# MSP432E401Y register map
Vendor: Texas Instruments; File version: 3.200
CPU: CM4 r1p2, little endian, no MPU, no FPU, 0x3 interrupt priority bits, 0x0 interrupts
Registers are 32-bit, read-write, no defined reset value unless marked. A register's access mark holds for its fields unless they carry their own. Offsets are from the block's base; [hi:lo] are bit positions; {n}, {i} and the like mark numbered series.

## ADC0 — Register map for ADC0 peripheral
Base 0x40038000; register names take the prefix ADC0
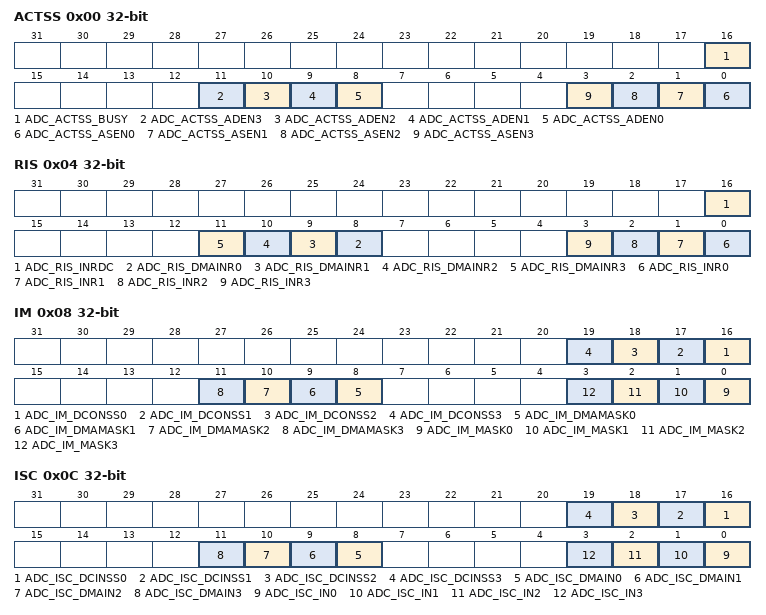
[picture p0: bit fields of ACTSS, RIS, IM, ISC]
0x00 ACTSS — ADC Active Sample Sequencer
  [16] ADC_ACTSS_BUSY — ADC Busy
  [11] ADC_ACTSS_ADEN3 — ADC SS3 DMA Enable
  [10] ADC_ACTSS_ADEN2 — ADC SS2 DMA Enable
  [9] ADC_ACTSS_ADEN1 — ADC SS1 DMA Enable
  [8] ADC_ACTSS_ADEN0 — ADC SS1 DMA Enable
  [n] ADC_ACTSS_ASEN{n} (n=0..3) — ADC SS{n} Enable
0x04 RIS — ADC Raw Interrupt Status
  [16] ADC_RIS_INRDC — Digital Comparator Raw Interrupt Status
  [n+8] ADC_RIS_DMAINR{n} (n=0..3) — SS{n} DMA Raw Interrupt Status
  [n] ADC_RIS_INR{n} (n=0..3) — SS{n} Raw Interrupt Status
0x08 IM — ADC Interrupt Mask
  [n+16] ADC_IM_DCONSS{n} (n=0..3) — Digital Comparator Interrupt on SS{n}
  [n+8] ADC_IM_DMAMASK{n} (n=0..3) — SS{n} DMA Interrupt Mask
  [n] ADC_IM_MASK{n} (n=0..3) — SS{n} Interrupt Mask
0x0C ISC — ADC Interrupt Status and Clear
  [n+16] ADC_ISC_DCINSS{n} (n=0..3) — Digital Comparator Interrupt Status on SS{n}
  [n+8] ADC_ISC_DMAIN{n} (n=0..3) — SS{n} DMA Interrupt Status and Clear
  [n] ADC_ISC_IN{n} (n=0..3) — SS{n} Interrupt Status and Clear
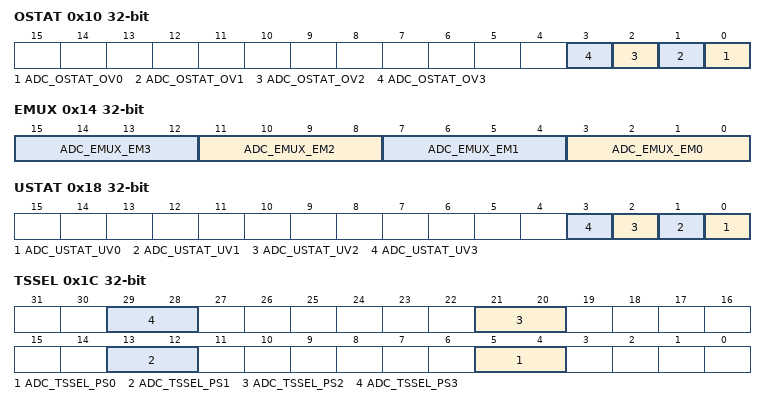
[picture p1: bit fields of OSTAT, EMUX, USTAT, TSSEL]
0x10 OSTAT — ADC Overflow Status
  [n] ADC_OSTAT_OV{n} (n=0..3) — SS{n} FIFO Overflow
0x14 EMUX — ADC Event Multiplexer Select
  [4n+3:4n] ADC_EMUX_EM{n} (n=0..3) — SS{n} Trigger Select
    0=ADC_EMUX_EM{n}_PROCESSOR (Processor (default)); 1=ADC_EMUX_EM{n}_COMP0 (Analog Comparator 0); 2=ADC_EMUX_EM{n}_COMP1 (Analog Comparator 1); 3=ADC_EMUX_EM{n}_COMP2 (Analog Comparator 2); 4=ADC_EMUX_EM{n}_EXTERNAL (External (GPIO Pins)); 5=ADC_EMUX_EM{n}_TIMER (Timer); {v}=ADC_EMUX_EM{n}_PWM{v-6} (PWM generator {v-6}) (v=6..9); 14=ADC_EMUX_EM{n}_NEVER (Never Trigger); 15=ADC_EMUX_EM{n}_ALWAYS (Always (continuously sample))
0x18 USTAT — ADC Underflow Status
  [n] ADC_USTAT_UV{n} (n=0..3) — SS{n} FIFO Underflow
0x1C TSSEL — ADC Trigger Source Select
  [8n+5:8n+4] ADC_TSSEL_PS{n} (n=0..3) — Generator {n} PWM Module Trigger Select
    0=Use Generator {n} (and its trigger) in PWM module 0
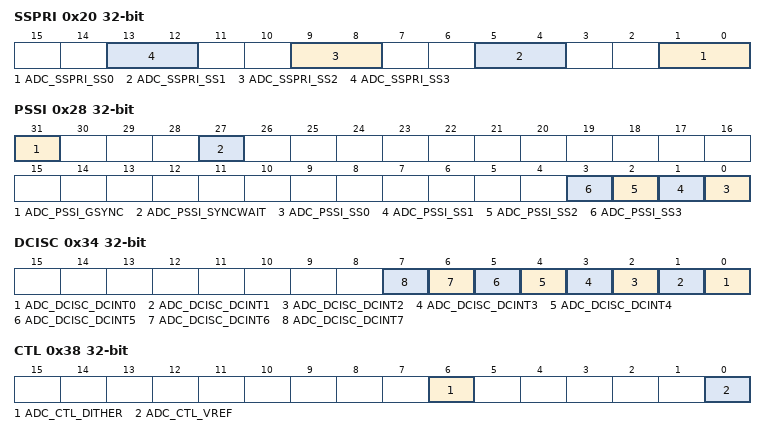
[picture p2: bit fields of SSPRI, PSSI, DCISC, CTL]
0x20 SSPRI — ADC Sample Sequencer Priority
  [4n+1:4n] ADC_SSPRI_SS{n} (n=0..3) — SS{n} Priority
0x24 SPC — ADC Sample Phase Control
  [3:0] ADC_SPC_PHASE — Phase Difference
    0=ADC sample lags by 0.0; 1=ADC_SPC_PHASE_22_5 (ADC sample lags by 22.5); 2=ADC sample lags by 45.0; 3=ADC_SPC_PHASE_67_5 (ADC sample lags by 67.5); 4=ADC sample lags by 90.0; 5=ADC_SPC_PHASE_112_5 (ADC sample lags by 112.5); 6=ADC sample lags by 135.0; 7=ADC_SPC_PHASE_157_5 (ADC sample lags by 157.5); 8=ADC sample lags by 180.0; 9=ADC_SPC_PHASE_202_5 (ADC sample lags by 202.5); 10=ADC sample lags by 225.0; 11=ADC_SPC_PHASE_247_5 (ADC sample lags by 247.5); 12=ADC sample lags by 270.0; 13=ADC_SPC_PHASE_292_5 (ADC sample lags by 292.5); 14=ADC sample lags by 315.0; 15=ADC_SPC_PHASE_337_5 (ADC sample lags by 337.5)
0x28 PSSI — ADC Processor Sample Sequence Initiate
  [31] ADC_PSSI_GSYNC — Global Synchronize
  [27] ADC_PSSI_SYNCWAIT — Synchronize Wait
  [n] ADC_PSSI_SS{n} (n=0..3) — SS{n} Initiate
0x30 SAC — ADC Sample Averaging Control
  [2:0] ADC_SAC_AVG — Hardware Averaging Control
    0=ADC_SAC_AVG_OFF (No hardware oversampling); 1=ADC_SAC_AVG_2X (2x hardware oversampling); 2=ADC_SAC_AVG_4X (4x hardware oversampling); 3=ADC_SAC_AVG_8X (8x hardware oversampling); 4=ADC_SAC_AVG_16X (16x hardware oversampling); 5=ADC_SAC_AVG_32X (32x hardware oversampling); 6=ADC_SAC_AVG_64X (64x hardware oversampling)
0x34 DCISC — ADC Digital Comparator Interrupt Status and Clear
  [n] ADC_DCISC_DCINT{n} (n=0..7) — Digital Comparator {n} Interrupt Status and Clear
0x38 CTL — ADC Control
  [6] ADC_CTL_DITHER — Dither Mode Enable
  [0] ADC_CTL_VREF — Voltage Reference Select
    0=ADC_CTL_VREF_INTERNAL (VDDA and GNDA are the voltage references); 1=ADC_CTL_VREF_EXT_3V (The external VREFA+ and VREFA- inputs are the voltage references)
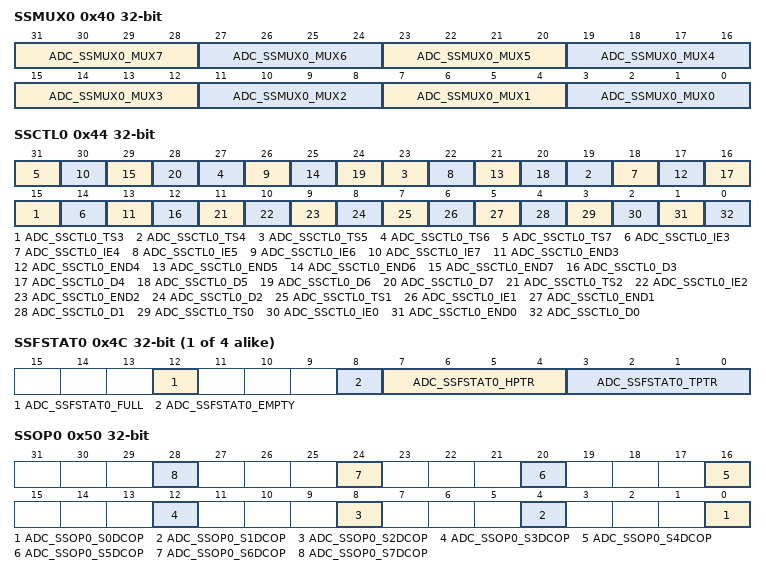
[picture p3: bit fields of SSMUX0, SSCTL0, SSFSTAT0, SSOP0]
0x40 SSMUX0 — ADC Sample Sequence Input Multiplexer Select 0
  [4n+3:4n] ADC_SSMUX0_MUX{n} (n=3..7) — {n+1}th Sample Input Select
  [11:8] ADC_SSMUX0_MUX2 — 3rd Sample Input Select
  [7:4] ADC_SSMUX0_MUX1 — 2nd Sample Input Select
  [3:0] ADC_SSMUX0_MUX0 — 1st Sample Input Select
0x44 SSCTL0 — ADC Sample Sequence Control 0
  [4n+3] ADC_SSCTL0_TS{n} (n=3..7) — {n+1}th Sample Temp Sensor Select
  [4n+2] ADC_SSCTL0_IE{n} (n=3..7) — {n+1}th Sample Interrupt Enable
  [4n+1] ADC_SSCTL0_END{n} (n=3..7) — {n+1}th Sample is End of Sequence
  [4n] ADC_SSCTL0_D{n} (n=3..7) — {n+1}th Sample Differential Input Select
  [11] ADC_SSCTL0_TS2 — 3rd Sample Temp Sensor Select
  [10] ADC_SSCTL0_IE2 — 3rd Sample Interrupt Enable
  [9] ADC_SSCTL0_END2 — 3rd Sample is End of Sequence
  [8] ADC_SSCTL0_D2 — 3rd Sample Differential Input Select
  [7] ADC_SSCTL0_TS1 — 2nd Sample Temp Sensor Select
  [6] ADC_SSCTL0_IE1 — 2nd Sample Interrupt Enable
  [5] ADC_SSCTL0_END1 — 2nd Sample is End of Sequence
  [4] ADC_SSCTL0_D1 — 2nd Sample Differential Input Select
  [3] ADC_SSCTL0_TS0 — 1st Sample Temp Sensor Select
  [2] ADC_SSCTL0_IE0 — 1st Sample Interrupt Enable
  [1] ADC_SSCTL0_END0 — 1st Sample is End of Sequence
  [0] ADC_SSCTL0_D0 — 1st Sample Differential Input Select
{0x48+0x20*i} SSFIFO{i} (i=0..3) — ADC Sample Sequence Result FIFO {i}
  [11:0] ADC_SSFIFO{i}_DATA — Conversion Result Data
{0x4C+0x20*i} SSFSTAT{i} (i=0..3) — ADC Sample Sequence FIFO {i} Status
  [12] ADC_SSFSTAT{i}_FULL — FIFO Full
  [8] ADC_SSFSTAT{i}_EMPTY — FIFO Empty
  [7:4] ADC_SSFSTAT{i}_HPTR — FIFO Head Pointer
  [3:0] ADC_SSFSTAT{i}_TPTR — FIFO Tail Pointer
0x50 SSOP0 — ADC Sample Sequence 0 Operation
  [4n] ADC_SSOP0_S{n}DCOP (n=0..7) — Sample {n} Digital Comparator Operation
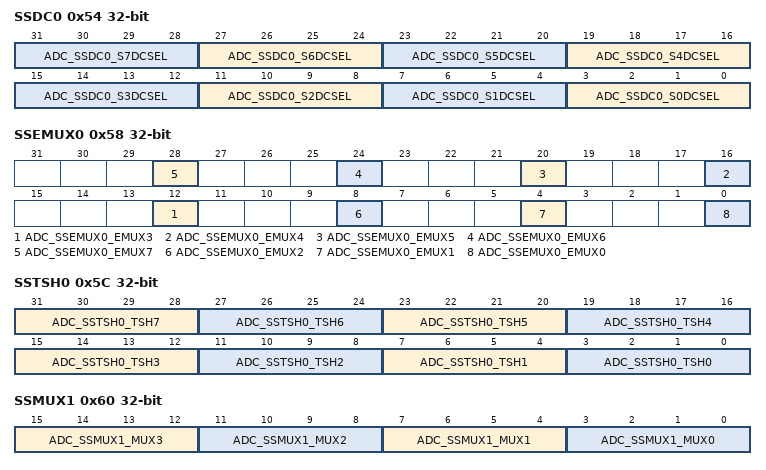
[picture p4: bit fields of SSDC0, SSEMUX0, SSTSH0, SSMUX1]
0x54 SSDC0 — ADC Sample Sequence 0 Digital Comparator Select
  [4n+3:4n] ADC_SSDC0_S{n}DCSEL (n=0..7) — Sample {n} Digital Comparator Select
0x58 SSEMUX0 — ADC Sample Sequence Extended Input Multiplexer Select 0
  [4n] ADC_SSEMUX0_EMUX{n} (n=3..7) — {n+1}th Sample Input Select (Upper Bit)
  [8] ADC_SSEMUX0_EMUX2 — 3rd Sample Input Select (Upper Bit)
  [4] ADC_SSEMUX0_EMUX1 — 2th Sample Input Select (Upper Bit)
  [0] ADC_SSEMUX0_EMUX0 — 1st Sample Input Select (Upper Bit)
0x5C SSTSH0 — ADC Sample Sequence 0 Sample and Hold Time
  [4n+3:4n] ADC_SSTSH0_TSH{n} (n=3..7) — {n+1}th Sample and Hold Period Select
  [11:8] ADC_SSTSH0_TSH2 — 3rd Sample and Hold Period Select
  [7:4] ADC_SSTSH0_TSH1 — 2nd Sample and Hold Period Select
  [3:0] ADC_SSTSH0_TSH0 — 1st Sample and Hold Period Select
0x60 SSMUX1 — ADC Sample Sequence Input Multiplexer Select 1
  [15:12] ADC_SSMUX1_MUX3 — 4th Sample Input Select
  [11:8] ADC_SSMUX1_MUX2 — 3rd Sample Input Select
  [7:4] ADC_SSMUX1_MUX1 — 2nd Sample Input Select
  [3:0] ADC_SSMUX1_MUX0 — 1st Sample Input Select
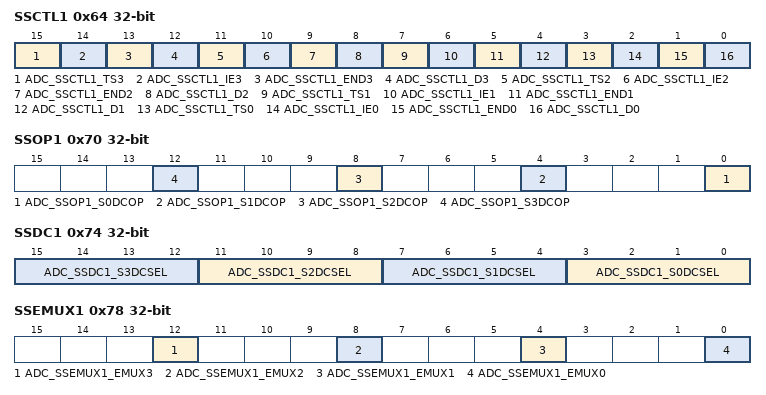
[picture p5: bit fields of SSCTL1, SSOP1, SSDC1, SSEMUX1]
0x64 SSCTL1 — ADC Sample Sequence Control 1
  [15] ADC_SSCTL1_TS3 — 4th Sample Temp Sensor Select
  [14] ADC_SSCTL1_IE3 — 4th Sample Interrupt Enable
  [13] ADC_SSCTL1_END3 — 4th Sample is End of Sequence
  [12] ADC_SSCTL1_D3 — 4th Sample Differential Input Select
  [11] ADC_SSCTL1_TS2 — 3rd Sample Temp Sensor Select
  [10] ADC_SSCTL1_IE2 — 3rd Sample Interrupt Enable
  [9] ADC_SSCTL1_END2 — 3rd Sample is End of Sequence
  [8] ADC_SSCTL1_D2 — 3rd Sample Differential Input Select
  [7] ADC_SSCTL1_TS1 — 2nd Sample Temp Sensor Select
  [6] ADC_SSCTL1_IE1 — 2nd Sample Interrupt Enable
  [5] ADC_SSCTL1_END1 — 2nd Sample is End of Sequence
  [4] ADC_SSCTL1_D1 — 2nd Sample Differential Input Select
  [3] ADC_SSCTL1_TS0 — 1st Sample Temp Sensor Select
  [2] ADC_SSCTL1_IE0 — 1st Sample Interrupt Enable
  [1] ADC_SSCTL1_END0 — 1st Sample is End of Sequence
  [0] ADC_SSCTL1_D0 — 1st Sample Differential Input Select
0x70 SSOP1 — ADC Sample Sequence 1 Operation
  [4n] ADC_SSOP1_S{n}DCOP (n=0..3) — Sample {n} Digital Comparator Operation
0x74 SSDC1 — ADC Sample Sequence 1 Digital Comparator Select
  [4n+3:4n] ADC_SSDC1_S{n}DCSEL (n=0..3) — Sample {n} Digital Comparator Select
0x78 SSEMUX1 — ADC Sample Sequence Extended Input Multiplexer Select 1
  [12] ADC_SSEMUX1_EMUX3 — 4th Sample Input Select (Upper Bit)
  [8] ADC_SSEMUX1_EMUX2 — 3rd Sample Input Select (Upper Bit)
  [4] ADC_SSEMUX1_EMUX1 — 2th Sample Input Select (Upper Bit)
  [0] ADC_SSEMUX1_EMUX0 — 1st Sample Input Select (Upper Bit)
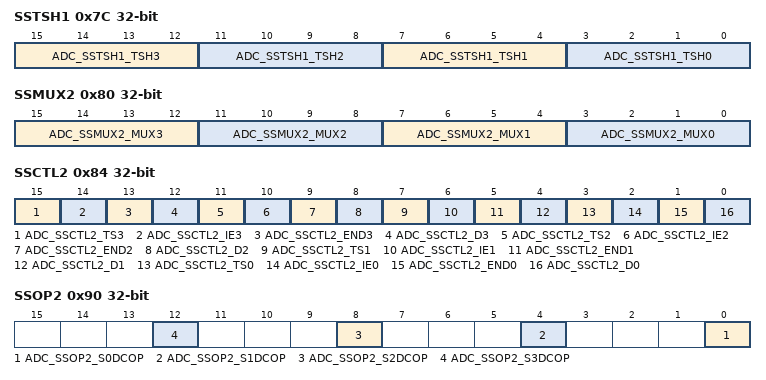
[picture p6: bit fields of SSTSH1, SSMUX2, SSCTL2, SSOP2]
0x7C SSTSH1 — ADC Sample Sequence 1 Sample and Hold Time
  [15:12] ADC_SSTSH1_TSH3 — 4th Sample and Hold Period Select
  [11:8] ADC_SSTSH1_TSH2 — 3rd Sample and Hold Period Select
  [7:4] ADC_SSTSH1_TSH1 — 2nd Sample and Hold Period Select
  [3:0] ADC_SSTSH1_TSH0 — 1st Sample and Hold Period Select
0x80 SSMUX2 — ADC Sample Sequence Input Multiplexer Select 2
  [15:12] ADC_SSMUX2_MUX3 — 4th Sample Input Select
  [11:8] ADC_SSMUX2_MUX2 — 3rd Sample Input Select
  [7:4] ADC_SSMUX2_MUX1 — 2nd Sample Input Select
  [3:0] ADC_SSMUX2_MUX0 — 1st Sample Input Select
0x84 SSCTL2 — ADC Sample Sequence Control 2
  [15] ADC_SSCTL2_TS3 — 4th Sample Temp Sensor Select
  [14] ADC_SSCTL2_IE3 — 4th Sample Interrupt Enable
  [13] ADC_SSCTL2_END3 — 4th Sample is End of Sequence
  [12] ADC_SSCTL2_D3 — 4th Sample Differential Input Select
  [11] ADC_SSCTL2_TS2 — 3rd Sample Temp Sensor Select
  [10] ADC_SSCTL2_IE2 — 3rd Sample Interrupt Enable
  [9] ADC_SSCTL2_END2 — 3rd Sample is End of Sequence
  [8] ADC_SSCTL2_D2 — 3rd Sample Differential Input Select
  [7] ADC_SSCTL2_TS1 — 2nd Sample Temp Sensor Select
  [6] ADC_SSCTL2_IE1 — 2nd Sample Interrupt Enable
  [5] ADC_SSCTL2_END1 — 2nd Sample is End of Sequence
  [4] ADC_SSCTL2_D1 — 2nd Sample Differential Input Select
  [3] ADC_SSCTL2_TS0 — 1st Sample Temp Sensor Select
  [2] ADC_SSCTL2_IE0 — 1st Sample Interrupt Enable
  [1] ADC_SSCTL2_END0 — 1st Sample is End of Sequence
  [0] ADC_SSCTL2_D0 — 1st Sample Differential Input Select
0x90 SSOP2 — ADC Sample Sequence 2 Operation
  [4n] ADC_SSOP2_S{n}DCOP (n=0..3) — Sample {n} Digital Comparator Operation
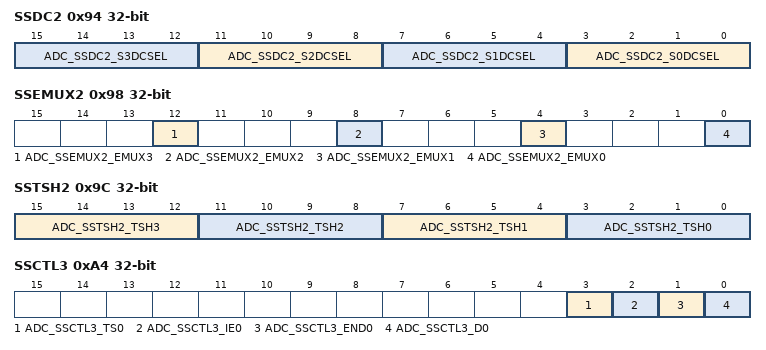
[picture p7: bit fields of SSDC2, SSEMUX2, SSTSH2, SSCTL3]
0x94 SSDC2 — ADC Sample Sequence 2 Digital Comparator Select
  [4n+3:4n] ADC_SSDC2_S{n}DCSEL (n=0..3) — Sample {n} Digital Comparator Select
0x98 SSEMUX2 — ADC Sample Sequence Extended Input Multiplexer Select 2
  [12] ADC_SSEMUX2_EMUX3 — 4th Sample Input Select (Upper Bit)
  [8] ADC_SSEMUX2_EMUX2 — 3rd Sample Input Select (Upper Bit)
  [4] ADC_SSEMUX2_EMUX1 — 2th Sample Input Select (Upper Bit)
  [0] ADC_SSEMUX2_EMUX0 — 1st Sample Input Select (Upper Bit)
0x9C SSTSH2 — ADC Sample Sequence 2 Sample and Hold Time
  [15:12] ADC_SSTSH2_TSH3 — 4th Sample and Hold Period Select
  [11:8] ADC_SSTSH2_TSH2 — 3rd Sample and Hold Period Select
  [7:4] ADC_SSTSH2_TSH1 — 2nd Sample and Hold Period Select
  [3:0] ADC_SSTSH2_TSH0 — 1st Sample and Hold Period Select
0xA0 SSMUX3 — ADC Sample Sequence Input Multiplexer Select 3
  [3:0] ADC_SSMUX3_MUX0 — 1st Sample Input Select
0xA4 SSCTL3 — ADC Sample Sequence Control 3
  [3] ADC_SSCTL3_TS0 — 1st Sample Temp Sensor Select
  [2] ADC_SSCTL3_IE0 — Sample Interrupt Enable
  [1] ADC_SSCTL3_END0 — End of Sequence
  [0] ADC_SSCTL3_D0 — Sample Differential Input Select
0xB0 SSOP3 — ADC Sample Sequence 3 Operation
  [0] ADC_SSOP3_S0DCOP — Sample 0 Digital Comparator Operation
0xB4 SSDC3 — ADC Sample Sequence 3 Digital Comparator Select
  [3:0] ADC_SSDC3_S0DCSEL — Sample 0 Digital Comparator Select
0xB8 SSEMUX3 — ADC Sample Sequence Extended Input Multiplexer Select 3
  [0] ADC_SSEMUX3_EMUX0 — 1st Sample Input Select (Upper Bit)
0xBC SSTSH3 — ADC Sample Sequence 3 Sample and Hold Time
  [3:0] ADC_SSTSH3_TSH0 — 1st Sample and Hold Period Select
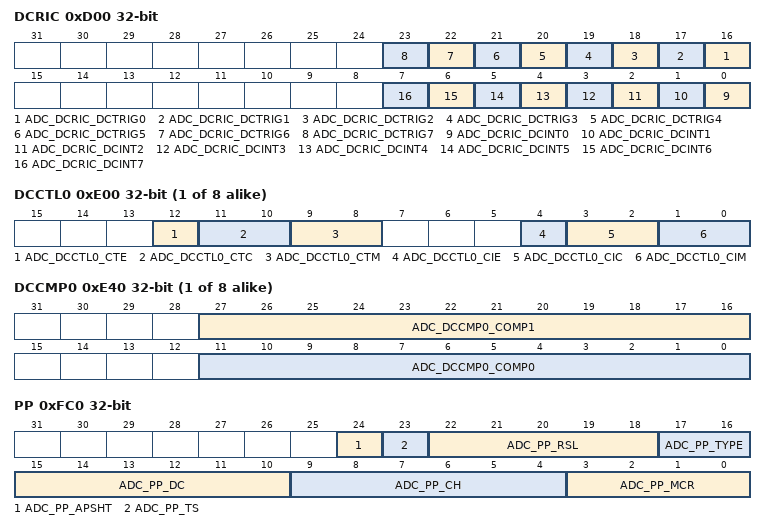
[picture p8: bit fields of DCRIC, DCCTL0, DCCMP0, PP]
0xD00 DCRIC wo — ADC Digital Comparator Reset Initial Conditions
  [n+16] ADC_DCRIC_DCTRIG{n} (n=0..7) — Digital Comparator Trigger {n}
  [n] ADC_DCRIC_DCINT{n} (n=0..7) — Digital Comparator Interrupt {n}
{0xE00+4i} DCCTL{i} (i=0..7) — ADC Digital Comparator Control {i}
  [12] ADC_DCCTL{i}_CTE — Comparison Trigger Enable
  [11:10] ADC_DCCTL{i}_CTC — Comparison Trigger Condition
    0=ADC_DCCTL{i}_CTC_LOW (Low Band); 1=ADC_DCCTL{i}_CTC_MID (Mid Band); 3=ADC_DCCTL{i}_CTC_HIGH (High Band)
  [9:8] ADC_DCCTL{i}_CTM — Comparison Trigger Mode
    0=ADC_DCCTL{i}_CTM_ALWAYS (Always); 1=ADC_DCCTL{i}_CTM_ONCE (Once); 2=ADC_DCCTL{i}_CTM_HALWAYS (Hysteresis Always); 3=ADC_DCCTL{i}_CTM_HONCE (Hysteresis Once)
  [4] ADC_DCCTL{i}_CIE — Comparison Interrupt Enable
  [3:2] ADC_DCCTL{i}_CIC — Comparison Interrupt Condition
    0=ADC_DCCTL{i}_CIC_LOW (Low Band); 1=ADC_DCCTL{i}_CIC_MID (Mid Band); 3=ADC_DCCTL{i}_CIC_HIGH (High Band)
  [1:0] ADC_DCCTL{i}_CIM — Comparison Interrupt Mode
    0=ADC_DCCTL{i}_CIM_ALWAYS (Always); 1=ADC_DCCTL{i}_CIM_ONCE (Once); 2=ADC_DCCTL{i}_CIM_HALWAYS (Hysteresis Always); 3=ADC_DCCTL{i}_CIM_HONCE (Hysteresis Once)
{0xE40+4i} DCCMP{i} (i=0..7) — ADC Digital Comparator Range {i}
  [27:16] ADC_DCCMP{i}_COMP1 — Compare 1
  [11:0] ADC_DCCMP{i}_COMP0 — Compare 0
0xFC0 PP — ADC Peripheral Properties
  [24] ADC_PP_APSHT — Application-Programmable Sample-and-Hold Time
  [23] ADC_PP_TS — Temperature Sensor
  [22:18] ADC_PP_RSL — Resolution
  [17:16] ADC_PP_TYPE — ADC Architecture
    0=ADC_PP_TYPE_SAR (SAR)
  [15:10] ADC_PP_DC — Digital Comparator Count
  [9:4] ADC_PP_CH — ADC Channel Count
  [3:0] ADC_PP_MCR — Maximum Conversion Rate
    7=ADC_PP_MCR_FULL (Full conversion rate (FCONV) as defined by TADC and NSH)
0xFC4 PC — ADC Peripheral Configuration
  [3:0] ADC_PC_MCR — Conversion Rate
    1=ADC_PC_MCR_1_8 (Eighth conversion rate. After a conversion completes, the logic pauses for 112 TADC periods before starting the next conversion); 3=ADC_PC_MCR_1_4 (Quarter conversion rate. After a conversion completes, the logic pauses for 48 TADC periods before starting the next conversion); 5=ADC_PC_MCR_1_2 (Half conversion rate. After a conversion completes, the logic pauses for 16 TADC periods before starting the next conversion); 7=ADC_PC_MCR_FULL (Full conversion rate (FCONV) as defined by TADC and NSH)
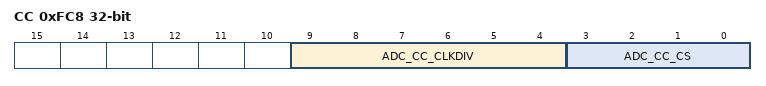
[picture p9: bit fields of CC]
0xFC8 CC — ADC Clock Configuration
  [9:4] ADC_CC_CLKDIV — PLL VCO Clock Divisor
  [3:0] ADC_CC_CS — ADC Clock Source
    0=ADC_CC_CS_SYSPLL (PLL VCO divided by CLKDIV); 1=ADC_CC_CS_PIOSC (PIOSC); 2=ADC_CC_CS_MOSC (MOSC)

## ADC1 — Register map for ADC0 peripheral
Base 0x40039000; register names take the prefix ADC1
Registers as ADC0.
